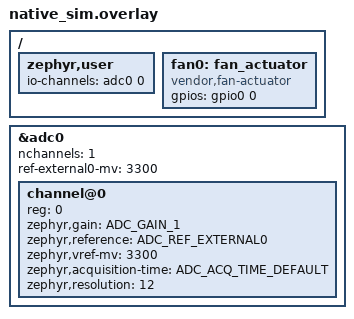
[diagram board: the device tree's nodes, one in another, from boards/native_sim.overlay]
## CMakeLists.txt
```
cmake_minimum_required(VERSION 3.20.0)
list(APPEND DTS_ROOT ${CMAKE_CURRENT_SOURCE_DIR})
find_package(Zephyr REQUIRED HINTS $ENV{ZEPHYR_BASE})
project(iot_app)
target_sources(app PRIVATE src/main.c src/actuator_logic.c src/fan_actuator.c)
target_include_directories(app PRIVATE dts/bindings/actuator)
```

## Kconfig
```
mainmenu "IoT Demo Application Configuration"

config IOT_TEMP_THRESHOLD_C
	int "Prag temperature za aktivaciju ventilatora (C)"
	default 30
	help
	  Kada ocitana temperatura pređe ovu vrednost, aktuator (LED/ventilator)
	  se aktivira. Ova vrednost se koristi kao inicijalna vrednost pri
	  pokretanju; moze se naknadno promeniti u runtime preko shell komande
	  'iot set_threshold'.

source "$(APPLICATION_SOURCE_DIR)/src/Kconfig"
source "Kconfig.zephyr"
```

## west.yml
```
manifest:
  version: 1.2

  self:
    path: iot_app

  projects:
    - name: zephyr
      revision: v4.3.0
      url: https://github.com/zephyrproject-rtos/zephyr
      path: ../zephyr
```

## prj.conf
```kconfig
CONFIG_ADC=y
CONFIG_ADC_EMUL=y
CONFIG_GPIO=y
CONFIG_LOG=y
CONFIG_SHELL=y
CONFIG_THREAD_NAME=y
CONFIG_ASSERT=y
CONFIG_IOT_TEMP_THRESHOLD_C=30
CONFIG_FAN_ACTUATOR=y
CONFIG_GPIO_EMUL=y
```

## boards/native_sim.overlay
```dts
/ {
    zephyr,user {
        io-channels = <&adc0 0>;
    };
    
    fan0: fan_actuator {
        compatible = "vendor,fan-actuator";
        status = "okay";
        gpios = <&gpio0 0 GPIO_ACTIVE_HIGH>;
    };
};

&adc0 {
    #address-cells = <1>;
    #size-cells = <0>;
    nchannels = <1>;
    ref-external0-mv = <3300>;

    channel@0 {
        reg = <0>;
        zephyr,gain = "ADC_GAIN_1";
        zephyr,reference = "ADC_REF_EXTERNAL0";
        zephyr,vref-mv = <3300>;
        zephyr,acquisition-time = <ADC_ACQ_TIME_DEFAULT>;
        zephyr,resolution = <12>;
    };
};
```

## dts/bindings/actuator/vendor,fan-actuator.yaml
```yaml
description: Simple fan actuator controlled via a single GPIO (LED)

compatible: "vendor,fan-actuator"

properties:
  gpios:
    type: phandle-array
    required: true
    description: GPIO pin connected to the fan/LED
```

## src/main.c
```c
#include <zephyr/kernel.h>
#include <zephyr/device.h>
#include <zephyr/devicetree.h>
#include <zephyr/drivers/gpio.h>
#include <zephyr/drivers/adc.h>
#include <zephyr/drivers/adc/adc_emul.h>
#include <zephyr/logging/log.h>
#include <zephyr/shell/shell.h>
#include <stdlib.h>
#include "actuator_logic.h"
#include "fan_actuator.h"

LOG_MODULE_REGISTER(iot_app, LOG_LEVEL_INF);

static const struct device *fan_dev = DEVICE_DT_GET(DT_NODELABEL(fan0));

// "Senzor": ADC kanal definisan u overlay-u
static const struct adc_dt_spec adc_channel = ADC_DT_SPEC_GET(DT_PATH(zephyr_user));

// Deljeno stanje, zaštićeno mutex-om
static struct k_mutex state_mutex;
static int32_t current_temp_c = 20;
static int32_t threshold_c = CONFIG_IOT_TEMP_THRESHOLD_C;
static bool fan_on;

// Sinhronizacija između thread-ova
K_SEM_DEFINE(sensor_ready_sem, 0, 1);

#define SENSOR_STACK_SIZE 1024
#define ACTUATOR_STACK_SIZE 1024
#define SENSOR_PRIORITY 5
#define ACTUATOR_PRIORITY 5

static void sensor_thread(void *a, void *b, void *c)
{
    ARG_UNUSED(a); ARG_UNUSED(b); ARG_UNUSED(c);

    int16_t buf;
    struct adc_sequence sequence = {
        .buffer = &buf,
        .buffer_size = sizeof(buf),
    };
    adc_sequence_init_dt(&adc_channel, &sequence);

    int setup_ret = adc_channel_setup_dt(&adc_channel);
    LOG_INF("adc_channel_setup_dt ret=%d", setup_ret);

    static int32_t sim_mv = 500;
    static int8_t sim_dir = 1;

    while (1) {
        // Ubrizgavamo sledecu simuliranu vrednost napona u emulator
        sim_mv += sim_dir * 150;
        if (sim_mv >= 3000 || sim_mv <= 200) {
            sim_dir = -sim_dir;
        }
        int set_ret = adc_emul_const_value_set(adc_channel.dev, adc_channel.channel_id, sim_mv);

        int32_t val_mv = 0;
        int read_ret = adc_read_dt(&adc_channel, &sequence);
        if (read_ret == 0) {
            val_mv = buf;
            adc_raw_to_millivolts_dt(&adc_channel, &val_mv);
        }

        int32_t temp = 15 + (val_mv % 26);

        k_mutex_lock(&state_mutex, K_FOREVER);
        current_temp_c = temp;
        k_mutex_unlock(&state_mutex);

        LOG_INF("ADC raw=%d -> temp=%dC", val_mv, temp);

        k_sem_give(&sensor_ready_sem);
        k_msleep(2000);
    }
}

static void actuator_thread(void *a, void *b, void *c)
{
    ARG_UNUSED(a); ARG_UNUSED(b); ARG_UNUSED(c);

    while (1) {
        k_sem_take(&sensor_ready_sem, K_FOREVER);

        int32_t temp, thr;
        k_mutex_lock(&state_mutex, K_FOREVER);
        temp = current_temp_c;
        thr = threshold_c;
        k_mutex_unlock(&state_mutex);

        bool should_be_on = decide_fan_state(temp, thr);

        if (should_be_on != fan_on) {
            fan_on = should_be_on;
            if (fan_on) {
                fan_actuator_on(fan_dev);
            } else {
                fan_actuator_off(fan_dev);
            }
            LOG_INF("Fan actuator readback: pin state = %d", fan_actuator_get_state(fan_dev));
        }
    }
}

K_THREAD_DEFINE(sensor_tid, SENSOR_STACK_SIZE, sensor_thread, NULL, NULL, NULL,
                 SENSOR_PRIORITY, 0, 0);
K_THREAD_DEFINE(actuator_tid, ACTUATOR_STACK_SIZE, actuator_thread, NULL, NULL, NULL,
                 ACTUATOR_PRIORITY, 0, 0);

// Shell komande: interaktivno menjanje praga i čitanje stanja
static int cmd_set_threshold(const struct shell *sh, size_t argc, char **argv)
{
    int32_t new_thr = atoi(argv[1]);
    k_mutex_lock(&state_mutex, K_FOREVER);
    threshold_c = new_thr;
    k_mutex_unlock(&state_mutex);
    shell_print(sh, "Novi prag postavljen na %d C", new_thr);
    return 0;
}

static int cmd_status(const struct shell *sh, size_t argc, char **argv)
{
    k_mutex_lock(&state_mutex, K_FOREVER);
    shell_print(sh, "Temp=%dC Prag=%dC Ventilator=%s",
                current_temp_c, threshold_c, fan_on ? "ON" : "OFF");
    k_mutex_unlock(&state_mutex);
    return 0;
}

SHELL_STATIC_SUBCMD_SET_CREATE(sub_iot,
    SHELL_CMD_ARG(set_threshold, NULL, "Postavi prag temperature <C>", cmd_set_threshold, 2, 0),
    SHELL_CMD(status, NULL, "Prikazi trenutno stanje", cmd_status),
    SHELL_SUBCMD_SET_END
);
SHELL_CMD_REGISTER(iot, &sub_iot, "IoT demo komande", NULL);

int main(void)
{
    k_mutex_init(&state_mutex);
    LOG_INF("Zephyr IoT Demo pokrenut (native_sim)");
    return 0;
}
```

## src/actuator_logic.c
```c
#include "actuator_logic.h"

bool decide_fan_state(int32_t temp, int32_t threshold)
{
    return temp >= threshold;
}
```

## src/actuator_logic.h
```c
#ifndef ACTUATOR_LOGIC_H
#define ACTUATOR_LOGIC_H

#include <stdbool.h>
#include <stdint.h>

bool decide_fan_state(int32_t temp, int32_t threshold);

#endif
```

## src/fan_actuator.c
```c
#define DT_DRV_COMPAT vendor_fan_actuator

#include <zephyr/kernel.h>
#include <zephyr/device.h>
#include <zephyr/drivers/gpio.h>
#include <zephyr/drivers/gpio/gpio_emul.h>
#include <zephyr/logging/log.h>
#include "fan_actuator.h"

LOG_MODULE_REGISTER(fan_actuator, LOG_LEVEL_INF);

struct fan_actuator_config {
    struct gpio_dt_spec gpio;
};

static int fan_actuator_init(const struct device *dev)
{
    const struct fan_actuator_config *cfg = dev->config;

    if (!gpio_is_ready_dt(&cfg->gpio)) {
        LOG_ERR("Fan actuator GPIO not ready");
        return -ENODEV;
    }

    int ret = gpio_pin_configure_dt(&cfg->gpio, GPIO_OUTPUT_INACTIVE);
    if (ret < 0) {
        LOG_ERR("Failed to configure fan actuator GPIO");
        return ret;
    }

    LOG_INF("Fan actuator driver initialized");
    return 0;
}

int fan_actuator_on(const struct device *dev)
{
    const struct fan_actuator_config *cfg = dev->config;
    return gpio_pin_set_dt(&cfg->gpio, 1);
}

int fan_actuator_off(const struct device *dev)
{
    const struct fan_actuator_config *cfg = dev->config;
    return gpio_pin_set_dt(&cfg->gpio, 0);
}

int fan_actuator_get_state(const struct device *dev)
{
    const struct fan_actuator_config *cfg = dev->config;

    // Ocitavamo stvarno stanje pina iz GPIO emulatora
    const struct device *port_dev = cfg->gpio.port;
    return gpio_emul_output_get(port_dev, cfg->gpio.pin);
}

#define FAN_ACTUATOR_INIT(inst)                                    \
    static const struct fan_actuator_config fan_actuator_cfg_##inst = { \
        .gpio = GPIO_DT_SPEC_INST_GET(inst, gpios),                \
    };                                                              \
    DEVICE_DT_INST_DEFINE(inst,                                     \
                          fan_actuator_init,                        \
                          NULL,                                     \
                          NULL,                                     \
                          &fan_actuator_cfg_##inst,                 \
                          POST_KERNEL,                               \
                          CONFIG_GPIO_INIT_PRIORITY,                \
                          NULL);

DT_INST_FOREACH_STATUS_OKAY(FAN_ACTUATOR_INIT)
```

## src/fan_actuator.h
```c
#ifndef FAN_ACTUATOR_H
#define FAN_ACTUATOR_H

#include <zephyr/device.h>

int fan_actuator_on(const struct device *dev);
int fan_actuator_off(const struct device *dev);
int fan_actuator_get_state(const struct device *dev);

#endif
```
